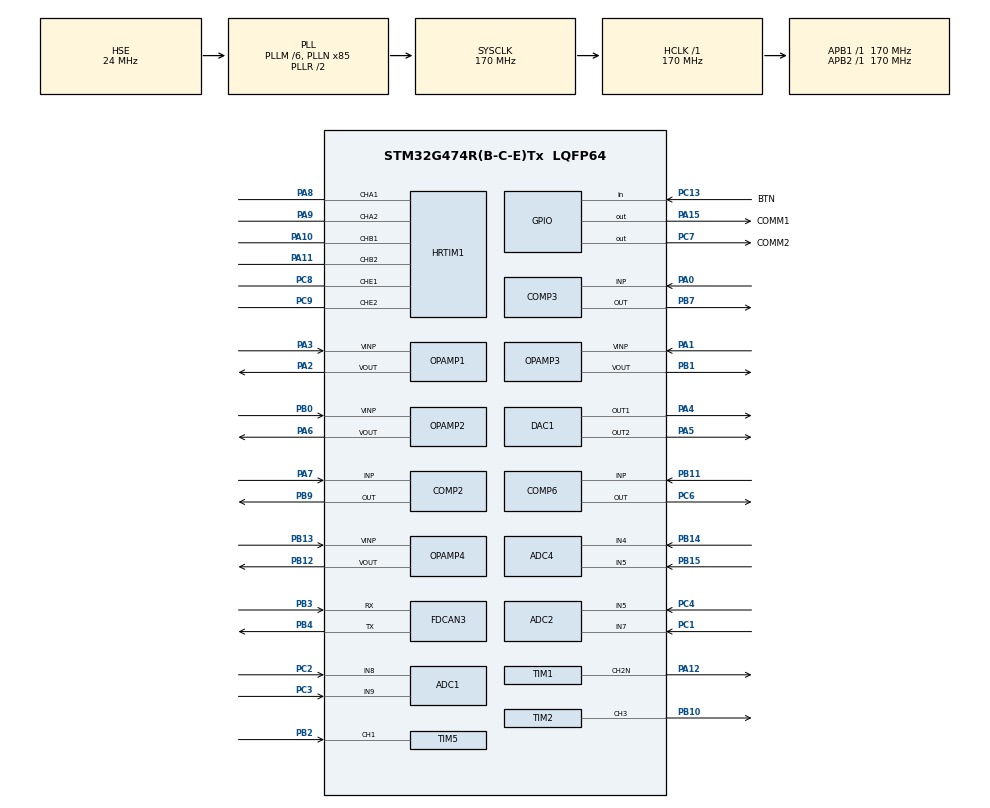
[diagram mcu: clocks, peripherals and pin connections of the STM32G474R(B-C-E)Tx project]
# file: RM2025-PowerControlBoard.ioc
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ADC1.AWD1HighThreshold=4095
ADC1.AWD2HighThreshold=4095
ADC1.AWD3HighThreshold=4095
ADC1.AWDChannel-8\#ChannelRegularConversion=ADC_CHANNEL_9
ADC1.AWDChannel-9\#ChannelRegularConversion=ADC_CHANNEL_8
ADC1.Channel-10\#ChannelRegularConversion=ADC_CHANNEL_12
ADC1.Channel-11\#ChannelRegularConversion=ADC_CHANNEL_3
ADC1.Channel-8\#ChannelRegularConversion=ADC_CHANNEL_9
ADC1.Channel-9\#ChannelRegularConversion=ADC_CHANNEL_8
ADC1.DMAAccessModeView=ENABLE
ADC1.DMAContinuousRequests=ENABLE
ADC1.EnableAnalogWatchDog1=true
ADC1.EnableAnalogWatchDog2=true
ADC1.EnableAnalogWatchDog3=true
ADC1.ExternalTrigConv=ADC_EXTERNALTRIG_HRTIM_TRG1
ADC1.Mode=ADC_DUALMODE_REGSIMULT
ADC1.MonitoredBy-10\#ChannelRegularConversion=__NULL
ADC1.MonitoredBy-11\#ChannelRegularConversion=__NULL
ADC1.MonitoredBy-8\#ChannelRegularConversion=ADC_ANALOGWATCHDOG_2
ADC1.MonitoredBy-9\#ChannelRegularConversion=ADC_ANALOGWATCHDOG_3
ADC1.NbrOfConversion=4
ADC1.NbrOfConversionFlag=1
ADC1.OffsetNumber-10\#ChannelRegularConversion=ADC_OFFSET_NONE
ADC1.OffsetNumber-11\#ChannelRegularConversion=ADC_OFFSET_NONE
ADC1.OffsetNumber-8\#ChannelRegularConversion=ADC_OFFSET_NONE
ADC1.OffsetNumber-9\#ChannelRegularConversion=ADC_OFFSET_NONE
ADC1.Overrun=ADC_OVR_DATA_OVERWRITTEN
ADC1.Rank-10\#ChannelRegularConversion=3
ADC1.Rank-11\#ChannelRegularConversion=4
ADC1.Rank-8\#ChannelRegularConversion=1
ADC1.Rank-9\#ChannelRegularConversion=2
ADC1.RegFilteringConfig-10\#ChannelRegularConversion=ADC_AWD_FILTERING_NONE
ADC1.RegFilteringConfig-8\#ChannelRegularConversion=ADC_AWD_FILTERING_NONE
ADC1.RegFilteringConfig-9\#ChannelRegularConversion=ADC_AWD_FILTERING_NONE
ADC1.SamplingTime-10\#ChannelRegularConversion=ADC_SAMPLETIME_12CYCLES_5
ADC1.SamplingTime-11\#ChannelRegularConversion=ADC_SAMPLETIME_12CYCLES_5
ADC1.SamplingTime-8\#ChannelRegularConversion=ADC_SAMPLETIME_12CYCLES_5
ADC1.SamplingTime-9\#ChannelRegularConversion=ADC_SAMPLETIME_12CYCLES_5
ADC1.WDG2ChannelR1=ADC_CHANNEL_9
ADC1.WDG3ChannelR2=ADC_CHANNEL_8
ADC1.WatchdogChannel=ADC_CHANNEL_12
ADC1.WatchdogMode2=ADC_ANALOGWATCHDOG_SINGLE_REGINJEC
ADC1.WatchdogMode3=ADC_ANALOGWATCHDOG_SINGLE_REGINJEC
ADC1.master=1
ADC2.AWD1HighThreshold=4095
ADC2.AWD2HighThreshold=4095
ADC2.AWD2ITMode=ENABLE
ADC2.AWDChannel-12\#ChannelRegularConversion=ADC_CHANNEL_5
ADC2.Channel-12\#ChannelRegularConversion=ADC_CHANNEL_5
ADC2.Channel-13\#ChannelRegularConversion=ADC_CHANNEL_3
ADC2.Channel-14\#ChannelRegularConversion=ADC_CHANNEL_3
ADC2.Channel-15\#ChannelRegularConversion=ADC_CHANNEL_7
ADC2.DMAAccessModeView=ENABLE
ADC2.DMAContinuousRequests=DISABLE
ADC2.EnableAnalogWatchDog1=true
ADC2.EnableAnalogWatchDog2=true
ADC2.EnableAnalogWatchDog3=false
ADC2.Mode=ADC_DUALMODE_REGSIMULT
ADC2.MonitoredBy-12\#ChannelRegularConversion=ADC_ANALOGWATCHDOG_2
ADC2.MonitoredBy-14\#ChannelRegularConversion=__NULL
ADC2.MonitoredBy-15\#ChannelRegularConversion=__NULL
ADC2.NbrOfConversion=4
ADC2.NbrOfConversionFlag=1
ADC2.OffsetNumber-12\#ChannelRegularConversion=ADC_OFFSET_NONE
ADC2.OffsetNumber-13\#ChannelRegularConversion=ADC_OFFSET_NONE
ADC2.OffsetNumber-14\#ChannelRegularConversion=ADC_OFFSET_NONE
ADC2.OffsetNumber-15\#ChannelRegularConversion=ADC_OFFSET_NONE
ADC2.Overrun=ADC_OVR_DATA_OVERWRITTEN
ADC2.Rank-12\#ChannelRegularConversion=1
ADC2.Rank-13\#ChannelRegularConversion=2
ADC2.Rank-14\#ChannelRegularConversion=3
ADC2.Rank-15\#ChannelRegularConversion=4
ADC2.RegFilteringConfig-12\#ChannelRegularConversion=ADC_AWD_FILTERING_NONE
ADC2.RegFilteringConfig-14\#ChannelRegularConversion=ADC_AWD_FILTERING_NONE
ADC2.SamplingTime-12\#ChannelRegularConversion=ADC_SAMPLETIME_12CYCLES_5
ADC2.SamplingTime-13\#ChannelRegularConversion=ADC_SAMPLETIME_12CYCLES_5
ADC2.SamplingTime-14\#ChannelRegularConversion=ADC_SAMPLETIME_12CYCLES_5
ADC2.SamplingTime-15\#ChannelRegularConversion=ADC_SAMPLETIME_12CYCLES_5
ADC2.WDG2ChannelR1=ADC_CHANNEL_5
ADC2.WatchdogChannel=ADC_CHANNEL_3
ADC2.WatchdogMode2=ADC_ANALOGWATCHDOG_SINGLE_REGINJEC
ADC4.Channel-3\#ChannelRegularConversion=ADC_CHANNEL_5
ADC4.Channel-4\#ChannelRegularConversion=ADC_CHANNEL_4
ADC4.DMAContinuousRequests=ENABLE
ADC4.ExternalTrigConv=ADC_SOFTWARE_START
ADC4.NbrOfConversion=2
ADC4.NbrOfConversionFlag=1
ADC4.OffsetNumber-3\#ChannelRegularConversion=ADC_OFFSET_NONE
ADC4.OffsetNumber-4\#ChannelRegularConversion=ADC_OFFSET_NONE
ADC4.Overrun=ADC_OVR_DATA_OVERWRITTEN
ADC4.Rank-3\#ChannelRegularConversion=1
ADC4.Rank-4\#ChannelRegularConversion=2
ADC4.SamplingTime-3\#ChannelRegularConversion=ADC_SAMPLETIME_247CYCLES_5
ADC4.SamplingTime-4\#ChannelRegularConversion=ADC_SAMPLETIME_92CYCLES_5
COMP2.Hysteresis=COMP_HYSTERESIS_NONE
COMP2.OutputPol=COMP_OUTPUTPOL_NONINVERTED
COMP2.TriggerMode=COMP_TRIGGERMODE_NONE
COMP3.TriggerMode=COMP_TRIGGERMODE_NONE
DAC1.DAC_Channel-DAC_OUT2_ExtAndInt=DAC_CHANNEL_2
DAC1.DAC_Channel-DAC_OUT2_Int=DAC_CHANNEL_2
DAC1.DAC_DMADoubleDataMode-DAC_OUT2_ExtAndInt=ENABLE
DAC1.DAC_HighFrequency_OUT1-DAC_OUT1_ExtAndInt=DAC_HIGH_FREQUENCY_INTERFACE_MODE_ABOVE_160MHZ
DAC1.DAC_HighFrequency_OUT2-DAC_OUT2_ExtAndInt=DAC_HIGH_FREQUENCY_INTERFACE_MODE_ABOVE_160MHZ
DAC1.DAC_HighFrequency_OUT2-DAC_OUT2_Int=DAC_HIGH_FREQUENCY_INTERFACE_MODE_ABOVE_160MHZ
DAC1.DAC_SampleAndHold-DAC_OUT1_ExtAndInt=DAC_SAMPLEANDHOLD_DISABLE
DAC1.DAC_SignedFormat-DAC_OUT2_ExtAndInt=ENABLE
DAC1.DAC_Trigger2_OUT1-DAC_OUT1_ExtAndInt=DAC_TRIGGER_HRTIM_STEP_TRG2
DAC1.DAC_Trigger2_OUT2-DAC_OUT2_ExtAndInt=DAC_TRIGGER_HRTIM_STEP_TRG1
DAC1.DAC_Trigger2_OUT2-DAC_OUT2_Int=DAC_TRIGGER_HRTIM_STEP_TRG1
DAC1.DAC_Trigger_OUT1-DAC_OUT1_ExtAndInt=DAC_TRIGGER_HRTIM_RST_TRG2
DAC1.DAC_Trigger_OUT2-DAC_OUT2_ExtAndInt=DAC_TRIGGER_HRTIM_RST_TRG1
DAC1.DAC_Trigger_OUT2-DAC_OUT2_Int=DAC_TRIGGER_HRTIM_RST_TRG1
DAC1.DAC_UserTrimming-DAC_OUT1_ExtAndInt=DAC_TRIMMING_FACTORY
DAC1.PolaritySawtooth2-DAC_OUT2_ExtAndInt=DAC_SAWTOOTH_POLARITY_INCREMENT
DAC1.ResetDataSawtooth-DAC_OUT1_ExtAndInt=2300
DAC1.ResetDataSawtooth2-DAC_OUT2_ExtAndInt=2300
DAC1.ResetDataSawtooth2-DAC_OUT2_Int=2300
DAC1.StepDataSawtooth-DAC_OUT1_ExtAndInt=500
DAC1.StepDataSawtooth2-DAC_OUT2_ExtAndInt=20
DAC1.StepDataSawtooth2-DAC_OUT2_Int=20
DAC1.WaveGeneration_OUT1-DAC_OUT1_ExtAndInt=SawtoothWaveGenerate
DAC1.WaveGeneration_OUT2-DAC_OUT2_ExtAndInt=SawtoothWaveGenerate
DAC1.WaveGeneration_OUT2-DAC_OUT2_Int=SawtoothWaveGenerate
Dma.ADC1.1.Direction=DMA_PERIPH_TO_MEMORY
Dma.ADC1.1.EventEnable=DISABLE
Dma.ADC1.1.Instance=DMA1_Channel1
Dma.ADC1.1.MemDataAlignment=DMA_MDATAALIGN_WORD
Dma.ADC1.1.MemInc=DMA_MINC_ENABLE
Dma.ADC1.1.Mode=DMA_CIRCULAR
Dma.ADC1.1.PeriphDataAlignment=DMA_PDATAALIGN_WORD
Dma.ADC1.1.PeriphInc=DMA_PINC_DISABLE
Dma.ADC1.1.Polarity=HAL_DMAMUX_REQ_GEN_RISING
Dma.ADC1.1.Priority=DMA_PRIORITY_VERY_HIGH
Dma.ADC1.1.RequestNumber=1
Dma.ADC1.1.SignalID=NONE
Dma.ADC1.1.SyncEnable=DISABLE
Dma.ADC1.1.SyncPolarity=HAL_DMAMUX_SYNC_NO_EVENT
Dma.ADC1.1.SyncRequestNumber=1
Dma.ADC1.1.SyncSignalID=NONE
Dma.ADC4.0.Direction=DMA_PERIPH_TO_MEMORY
Dma.ADC4.0.EventEnable=DISABLE
Dma.ADC4.0.Instance=DMA2_Channel2
Dma.ADC4.0.MemDataAlignment=DMA_MDATAALIGN_WORD
Dma.ADC4.0.MemInc=DMA_MINC_ENABLE
Dma.ADC4.0.Mode=DMA_CIRCULAR
Dma.ADC4.0.PeriphDataAlignment=DMA_PDATAALIGN_WORD
Dma.ADC4.0.PeriphInc=DMA_PINC_DISABLE
Dma.ADC4.0.Polarity=HAL_DMAMUX_REQ_GEN_RISING
Dma.ADC4.0.Priority=DMA_PRIORITY_HIGH
Dma.ADC4.0.RequestNumber=1
Dma.ADC4.0.SignalID=NONE
Dma.ADC4.0.SyncEnable=DISABLE
Dma.ADC4.0.SyncPolarity=HAL_DMAMUX_SYNC_NO_EVENT
Dma.ADC4.0.SyncRequestNumber=1
Dma.ADC4.0.SyncSignalID=NONE
Dma.HRTIM1_E.3.Direction=DMA_MEMORY_TO_PERIPH
Dma.HRTIM1_E.3.EventEnable=DISABLE
Dma.HRTIM1_E.3.Instance=DMA1_Channel2
Dma.HRTIM1_E.3.MemDataAlignment=DMA_MDATAALIGN_WORD
Dma.HRTIM1_E.3.MemInc=DMA_MINC_ENABLE
Dma.HRTIM1_E.3.Mode=DMA_CIRCULAR
Dma.HRTIM1_E.3.PeriphDataAlignment=DMA_PDATAALIGN_WORD
Dma.HRTIM1_E.3.PeriphInc=DMA_PINC_DISABLE
Dma.HRTIM1_E.3.Polarity=HAL_DMAMUX_REQ_GEN_RISING
Dma.HRTIM1_E.3.Priority=DMA_PRIORITY_HIGH
Dma.HRTIM1_E.3.RequestNumber=1
Dma.HRTIM1_E.3.SignalID=NONE
Dma.HRTIM1_E.3.SyncEnable=DISABLE
Dma.HRTIM1_E.3.SyncPolarity=HAL_DMAMUX_SYNC_NO_EVENT
Dma.HRTIM1_E.3.SyncRequestNumber=1
Dma.HRTIM1_E.3.SyncSignalID=NONE
Dma.Request0=ADC4
Dma.Request1=ADC1
Dma.Request2=TIM2_CH3
Dma.Request3=HRTIM1_E
Dma.TIM2_CH3.2.Direction=DMA_MEMORY_TO_PERIPH
Dma.TIM2_CH3.2.EventEnable=DISABLE
Dma.TIM2_CH3.2.Instance=DMA2_Channel1
Dma.TIM2_CH3.2.MemDataAlignment=DMA_MDATAALIGN_WORD
Dma.TIM2_CH3.2.MemInc=DMA_MINC_ENABLE
Dma.TIM2_CH3.2.Mode=DMA_NORMAL
Dma.TIM2_CH3.2.PeriphDataAlignment=DMA_PDATAALIGN_WORD
Dma.TIM2_CH3.2.PeriphInc=DMA_PINC_DISABLE
Dma.TIM2_CH3.2.Polarity=HAL_DMAMUX_REQ_GEN_RISING
Dma.TIM2_CH3.2.Priority=DMA_PRIORITY_MEDIUM
Dma.TIM2_CH3.2.RequestNumber=1
Dma.TIM2_CH3.2.SignalID=NONE
Dma.TIM2_CH3.2.SyncEnable=DISABLE
Dma.TIM2_CH3.2.SyncPolarity=HAL_DMAMUX_SYNC_NO_EVENT
Dma.TIM2_CH3.2.SyncRequestNumber=1
Dma.TIM2_CH3.2.SyncSignalID=NONE
FDCAN3.CalculateBaudRateNominal=1000000
FDCAN3.CalculateTimeBitNominal=1000
FDCAN3.CalculateTimeQuantumNominal=100.0
FDCAN3.DataPrescaler=1
FDCAN3.DataTimeSeg1=1
FDCAN3.DataTimeSeg2=1
FDCAN3.NominalPrescaler=17
FDCAN3.NominalTimeSeg1=7
FDCAN3.NominalTimeSeg2=2
FDCAN3.StdFiltersNbr=1
HRTIM1.ADCTrigger1_Source1=HRTIM_ADCTRIGGEREVENT13_MASTER_CMP1
HRTIM1.ADCTrigger2_Source1=HRTIM_ADCTRIGGEREVENT24_MASTER_CMP3
HRTIM1.ADCTrigger_Id1=HRTIM_ADCTRIGGER_1
HRTIM1.ADCTrigger_Id2=HRTIM_ADCTRIGGER_2
HRTIM1.CaptureUnit1-Output_TA1TA2=__NULL
HRTIM1.CaptureUnit1-Output_TB1TB2=__NULL
HRTIM1.CaptureUnit2-Output_TA1TA2=__NULL
HRTIM1.CaptureUnit2-Output_TB1TB2=__NULL
HRTIM1.CompareUnit1-MasterTimer=HRTIM_COMPAREUNIT_1
HRTIM1.CompareUnit1-Output_TA1TA2=HRTIM_COMPAREUNIT_1
HRTIM1.CompareUnit1-Output_TB1TB2=HRTIM_COMPAREUNIT_1
HRTIM1.CompareUnit1-Output_TE1TE2=HRTIM_COMPAREUNIT_1
HRTIM1.CompareUnit2-MasterTimer=HRTIM_COMPAREUNIT_2
HRTIM1.CompareUnit2-Output_TA1TA2=HRTIM_COMPAREUNIT_2
HRTIM1.CompareUnit2-Output_TB1TB2=HRTIM_COMPAREUNIT_2
HRTIM1.CompareUnit2-Output_TE1TE2=__NULL
HRTIM1.CompareUnit3-MasterTimer=HRTIM_COMPAREUNIT_3
HRTIM1.CompareUnit3-Output_TA1TA2=HRTIM_COMPAREUNIT_3
HRTIM1.CompareUnit3-Output_TB1TB2=HRTIM_COMPAREUNIT_3
HRTIM1.CompareUnit3-Output_TE1TE2=HRTIM_COMPAREUNIT_3
HRTIM1.CompareUnit4-Output_TA1TA2=HRTIM_COMPAREUNIT_4
HRTIM1.CompareUnit4-Output_TB1TB2=HRTIM_COMPAREUNIT_4
HRTIM1.CompareUnit4-Output_TE1TE2=__NULL
HRTIM1.CompareValue1-MasterTimer=5000-416
HRTIM1.CompareValue1-Output_TA1TA2=0
HRTIM1.CompareValue1-Output_TB1TB2=0
HRTIM1.CompareValue1-Output_TE1TE2=0
HRTIM1.CompareValue2-MasterTimer=10880
HRTIM1.CompareValue2-Output_TA1TA2=1088
HRTIM1.CompareValue2-Output_TB1TB2=1088
HRTIM1.CompareValue3-MasterTimer=15000-2848
HRTIM1.CompareValue3-Output_TA1TA2=19000
HRTIM1.CompareValue3-Output_TB1TB2=8000
HRTIM1.CompareValue3-Output_TE1TE2=0
HRTIM1.CompareValue4-Output_TA1TA2=2176
HRTIM1.CompareValue4-Output_TB1TB2=2176
HRTIM1.CounterFaultLine5=0
HRTIM1.DACSynchro-Output_TA1TA2=HRTIM_DACSYNC_NONE
HRTIM1.DMADstAddress-Output_TE1TE2=(uint32_t)&(hhrtim1.Instance->sTimerxRegs[HRTIM_TIMERINDEX_TIMER_E].CMP1xR)
HRTIM1.DMARequests1-Output_TE1TE2=HRTIM_TIM_DMA_RST
HRTIM1.DMASize-Output_TE1TE2=4
HRTIM1.DMASrcAddress-Output_TE1TE2=(uint32_t)&timerE_Duty_DMA_Buffer[0]
HRTIM1.DeadTimeInsertion-Output_TA1TA2=HRTIM_TIMDEADTIMEINSERTION_ENABLED
HRTIM1.DeadTimeInsertion-Output_TB1TB2=HRTIM_TIMDEADTIMEINSERTION_ENABLED
HRTIM1.DeadTimeInsertion-Output_TE1TE2=HRTIM_TIMDEADTIMEINSERTION_ENABLED
HRTIM1.Deadtimeconfig-Output_TE1TE2=HRTIM_TIMERINDEX_TIMER_E
HRTIM1.DualChannelDacEnableFake_TA-Output_TA1TA2=HRTIM_TIMER_DCDE_ENABLED_FAKE1
HRTIM1.DualChannelDacEnableFake_TB-Output_TB1TB2=HRTIM_TIMER_DCDE_ENABLED_FAKE1
HRTIM1.Event1-Output_TA1TA2=__NULL
HRTIM1.Event1-Output_TE1TE2=__NULL
HRTIM1.Event2-Output_TA1TA2=__NULL
HRTIM1.Event5-Output_TB1TB2=__NULL
HRTIM1.Event6-Output_TA1TA2=HRTIM_EVENT_6
HRTIM1.Event6-Output_TB1TB2=__NULL
HRTIM1.Event8-Output_TA1TA2=__NULL
HRTIM1.Event8-Output_TB1TB2=HRTIM_EVENT_8
HRTIM1.Event_EEV1=HRTIM_EVENT_1
HRTIM1.Event_EEV2=HRTIM_EVENT_2
HRTIM1.Event_EEV3=HRTIM_EVENT_3
HRTIM1.Event_EEV4=HRTIM_EVENT_4
HRTIM1.Event_EEV5=HRTIM_EVENT_5
HRTIM1.Event_EEV6=HRTIM_EVENT_6
HRTIM1.Event_EEV7=__NULL
HRTIM1.Event_EEV8=HRTIM_EVENT_8
HRTIM1.Event_EEV9=__NULL
HRTIM1.FallingSign-Output_TA1TA2=HRTIM_TIMDEADTIME_FALLINGSIGN_POSITIVE
HRTIM1.FallingValue-Output_TA1TA2=40
HRTIM1.FallingValue-Output_TB1TB2=40
HRTIM1.FallingValue-Output_TE1TE2=40
HRTIM1.FaultEnable_Source1-Output_TA1TA2=HRTIM_TIMFAULTENABLE_FAULT1
HRTIM1.FaultEnable_Source1-Output_TB1TB2=HRTIM_TIMFAULTENABLE_FAULT1
HRTIM1.FaultEnable_Source2-Output_TA1TA2=HRTIM_TIMFAULTENABLE_FAULT2
HRTIM1.FaultEnable_Source2-Output_TB1TB2=HRTIM_TIMFAULTENABLE_FAULT2
HRTIM1.FaultEnable_Source3-Output_TA1TA2=HRTIM_TIMFAULTENABLE_FAULT3
HRTIM1.FaultEnable_Source3-Output_TB1TB2=HRTIM_TIMFAULTENABLE_FAULT3
HRTIM1.FaultEnable_Source4-Output_TA1TA2=HRTIM_TIMFAULTENABLE_FAULT4
HRTIM1.FaultEnable_Source4-Output_TB1TB2=HRTIM_TIMFAULTENABLE_FAULT4
HRTIM1.FaultEnable_Source5-Output_TA1TA2=HRTIM_TIMFAULTENABLE_FAULT5
HRTIM1.FaultEnable_Source5-Output_TB1TB2=HRTIM_TIMFAULTENABLE_FAULT5
HRTIM1.FaultLevel1-Output_TA1TA2=HRTIM_OUTPUTFAULTLEVEL_INACTIVE
HRTIM1.FaultLevel1-Output_TB1TB2=HRTIM_OUTPUTFAULTLEVEL_INACTIVE
HRTIM1.FaultLevel2-Output_TA1TA2=HRTIM_OUTPUTFAULTLEVEL_INACTIVE
HRTIM1.FaultLevel2-Output_TB1TB2=HRTIM_OUTPUTFAULTLEVEL_INACTIVE
HRTIM1.FaultLock-Output_TB1TB2=HRTIM_TIMFAULTLOCK_READWRITE
HRTIM1.Fault_Line1=HRTIM_FAULT_1
HRTIM1.Fault_Line2=HRTIM_FAULT_2
HRTIM1.Fault_Line3=HRTIM_FAULT_3
HRTIM1.Fault_Line4=HRTIM_FAULT_4
HRTIM1.Fault_Line5=HRTIM_FAULT_5
HRTIM1.Filter6-Output_TA1TA2=HRTIM_TIMEEVFLT_BLANKINGCMP4
HRTIM1.Filter8-Output_TB1TB2=HRTIM_TIMEEVFLT_BLANKINGCMP4
HRTIM1.Filter_FaultLine1=HRTIM_FAULTFILTER_3
HRTIM1.Filter_FaultLine2=HRTIM_FAULTFILTER_3
HRTIM1.Filter_FaultLine3=HRTIM_FAULTFILTER_6
HRTIM1.Filter_FaultLine4=HRTIM_FAULTFILTER_3
HRTIM1.Filter_FaultLine5=HRTIM_FAULTFILTER_9
HRTIM1.GreaterCMP1_TA=HRTIM_TIMERGTCMP1_EQUAL
HRTIM1.GreaterCMP3_TA=HRTIM_TIMERGTCMP3_EQUAL
HRTIM1.HRTIMInterruptResquests1=HRTIM_IT_NONE
HRTIM1.IdleLevel1-Output_TA1TA2=HRTIM_OUTPUTIDLELEVEL_INACTIVE
HRTIM1.IdleLevel2-Output_TA1TA2=HRTIM_OUTPUTIDLELEVEL_INACTIVE
HRTIM1.InterruptRequests1_Master=HRTIM_MASTER_IT_MUPD
HRTIM1.NumberADCTriggerSource1=1
HRTIM1.NumberADCTriggerSource2=1
HRTIM1.NumberDMARequests_TB=0
HRTIM1.NumberDMARequests_TE=1
HRTIM1.NumberFaultEnable-Output_TA1TA2=5
HRTIM1.NumberFaultEnable-Output_TB1TB2=5
HRTIM1.NumberInterruptRequests-Output_TA1TA2=0
HRTIM1.NumberInterruptRequests_Master-MasterTimer=1
HRTIM1.NumberResetSource1-Output_TA1TA2=1
HRTIM1.NumberResetSource1-Output_TB1TB2=1
HRTIM1.NumberResetSource1-Output_TE1TE2=1
HRTIM1.NumberResetTrigger-Output_TA1TA2=1
HRTIM1.NumberResetTrigger-Output_TB1TB2=1
HRTIM1.NumberResetTrigger-Output_TE1TE2=1
HRTIM1.NumberSetSource1-Output_TA1TA2=2
HRTIM1.NumberSetSource1-Output_TB1TB2=2
HRTIM1.NumberSetSource1-Output_TE1TE2=1
HRTIM1.NumberUpdateTrigger-Output_TA1TA2=1
HRTIM1.NumberUpdateTrigger-Output_TB1TB2=1
HRTIM1.NumberUpdateTrigger-Output_TE1TE2=1
HRTIM1.Periode_MASTER=21760
HRTIM1.Periode_TA=21760
HRTIM1.Periode_TB=21760
HRTIM1.Periode_TE=21760
HRTIM1.Polarity1-Output_TA1TA2=HRTIM_OUTPUTPOLARITY_HIGH
HRTIM1.Polarity2-Output_TA1TA2=HRTIM_OUTPUTPOLARITY_HIGH
HRTIM1.Polarity_EEV6=HRTIM_EVENTPOLARITY_LOW
HRTIM1.Polarity_EEV8=HRTIM_EVENTPOLARITY_LOW
HRTIM1.PreloadEnable-Output_TA1TA2=HRTIM_PRELOAD_ENABLED
HRTIM1.PreloadEnable-Output_TE1TE2=HRTIM_PRELOAD_ENABLED
HRTIM1.RepetitionCounter-MasterTimer=4-1
HRTIM1.RepetitionUpdate-Output_TA1TA2=HRTIM_UPDATEONREPETITION_ENABLED
HRTIM1.RepetitionUpdate-Output_TB1TB2=HRTIM_UPDATEONREPETITION_ENABLED
HRTIM1.RepetitionUpdate-Output_TE1TE2=HRTIM_UPDATEONREPETITION_ENABLED
HRTIM1.ResetModeFaultLine5=HRTIM_FAULTCOUNTERRST_UNCONDITIONAL
HRTIM1.ResetOutput1_Source1-Output_TA1TA2=HRTIM_OUTPUTRESET_TIMCMP1
HRTIM1.ResetOutput1_Source1-Output_TB1TB2=HRTIM_OUTPUTRESET_TIMCMP1
HRTIM1.ResetOutput1_Source1-Output_TE1TE2=HRTIM_OUTPUTRESET_TIMCMP1
HRTIM1.ResetTrigger1-Output_TA1TA2=HRTIM_TIMRESETTRIGGER_MASTER_PER
HRTIM1.ResetTrigger1-Output_TB1TB2=HRTIM_TIMRESETTRIGGER_MASTER_CMP2
HRTIM1.ResetTrigger1-Output_TE1TE2=HRTIM_TIMRESETTRIGGER_MASTER_PER
HRTIM1.RisingSign-Output_TA1TA2=HRTIM_TIMDEADTIME_RISINGSIGN_POSITIVE
HRTIM1.RisingValue-Output_TA1TA2=40
HRTIM1.RisingValue-Output_TB1TB2=40
HRTIM1.RisingValue-Output_TE1TE2=40
HRTIM1.SetOutput1_Source1-Output_TA1TA2=HRTIM_OUTPUTSET_TIMCMP3
HRTIM1.SetOutput1_Source1-Output_TB1TB2=HRTIM_OUTPUTSET_TIMCMP3
HRTIM1.SetOutput1_Source1-Output_TE1TE2=HRTIM_OUTPUTSET_TIMCMP3
HRTIM1.SetOutput1_Source2-Output_TA1TA2=HRTIM_OUTPUTSET_EEV_6
HRTIM1.SetOutput1_Source2-Output_TB1TB2=HRTIM_OUTPUTSET_EEV_8
HRTIM1.Source_EEV1=HRTIM_EEV1SRC_ADC1_AWD1
HRTIM1.Source_EEV2=HRTIM_EEV2SRC_ADC1_AWD2
HRTIM1.Source_EEV3=HRTIM_EEV3SRC_ADC1_AWD3
HRTIM1.Source_EEV4=HRTIM_EEV4SRC_ADC2_AWD1
HRTIM1.Source_EEV5=HRTIM_EEV5SRC_ADC2_AWD2
HRTIM1.Source_EEV8=HRTIM_EEV8SRC_COMP3_OUT
HRTIM1.Source_FaultLine1=HRTIM_FAULTSOURCE_EEVINPUT
HRTIM1.Source_FaultLine2=HRTIM_FAULTSOURCE_EEVINPUT
HRTIM1.Source_FaultLine3=HRTIM_FAULTSOURCE_EEVINPUT
HRTIM1.Source_FaultLine4=HRTIM_FAULTSOURCE_EEVINPUT
HRTIM1.Source_FaultLine5=HRTIM_FAULTSOURCE_EEVINPUT
HRTIM1.SwapA=__NULL
HRTIM1.UpdateTrigger1-Output_TA1TA2=HRTIM_TIMUPDATETRIGGER_MASTER
HRTIM1.UpdateTrigger1-Output_TB1TB2=HRTIM_TIMUPDATETRIGGER_MASTER
HRTIM1.UpdateTrigger1-Output_TE1TE2=HRTIM_TIMUPDATETRIGGER_MASTER
Mcu.Family=STM32G4
Mcu.Name=STM32G474R(B-C-E)Tx
Mcu.Package=LQFP64
Mcu.UserConstants=DEAD_TIME,60
NVIC.FDCAN3_IT0_IRQn=true\:1\:0\:true\:false\:false\:true\:true\:true
NVIC.HRTIM1_FLT_IRQn=true\:0\:0\:false\:false\:false\:true\:true\:true
NVIC.HRTIM1_Master_IRQn=true\:0\:0\:false\:false\:false\:true\:true\:true
NVIC.PriorityGroup=NVIC_PRIORITYGROUP_4
NVIC.TIM20_TRG_COM_IRQn=true\:2\:0\:true\:false\:true\:true\:true\:true
NVIC.TIM20_UP_IRQn=true\:2\:0\:true\:false\:true\:true\:true\:true
NVIC.TIM6_DAC_IRQn=true\:2\:0\:true\:false\:true\:true\:true\:true
OPAMP2.PowerMode=OPAMP_POWERMODE_HIGHSPEED
OPAMP3.PowerMode=OPAMP_POWERMODE_HIGHSPEED
PA0.Mode=INP
PA0.Signal=COMP3_INP
PA1.Mode=Follower
PA1.Signal=OPAMP3_VINP
PA10.Mode=Output_TB1TB2
PA10.Signal=HRTIM1_CHB1
PA11.Mode=Output_TB1TB2
PA11.Signal=HRTIM1_CHB2
PA12.Mode=PWM Generation2 CH2N
PA12.Signal=TIM1_CH2N
PA13.Mode=Serial_Wire
PA13.Signal=SYS_JTMS-SWDIO
PA14.Mode=Serial_Wire
PA14.Signal=SYS_JTCK-SWCLK
PA15.GPIO_Label=COMM1
PA15.GPIO_Speed=GPIO_SPEED_FREQ_VERY_HIGH
PA15.Signal=GPIO_Output
PA2.Signal=SharedAnalog_PA2
PA3.Mode=Follower
PA3.Signal=OPAMP1_VINP
PA4.Signal=COMP_DAC11_group
PA5.Signal=COMP_DAC12_group
PA6.Signal=SharedAnalog_PA6
PA7.Mode=INP
PA7.Signal=COMP2_INP
PA8.Mode=Output_TA1TA2
PA8.Signal=HRTIM1_CHA1
PA9.Mode=Output_TA1TA2
PA9.Signal=HRTIM1_CHA2
PB0.Mode=Follower
PB0.Signal=OPAMP2_VINP
PB1.Signal=SharedAnalog_PB1
PB10.Signal=S_TIM2_CH3
PB11.Mode=INP
PB11.Signal=COMP6_INP
PB12.Mode=Follower
PB12.Signal=OPAMP4_VOUT
PB13.Mode=Follower
PB13.Signal=OPAMP4_VINP
PB14.Mode=IN4-Single-Ended
PB14.Signal=ADC4_IN4
PB15.Mode=IN5-Single-Ended
PB15.Signal=ADC4_IN5
PB2.Signal=S_TIM5_CH1
PB3.GPIO_Speed=GPIO_SPEED_FREQ_LOW
PB3.Mode=FDCAN_Activate
PB3.Signal=FDCAN3_RX
PB4.Mode=FDCAN_Activate
PB4.Signal=FDCAN3_TX
PB7.Mode=ExternalOutput
PB7.Signal=COMP3_OUT
PB9.GPIO_FM9=__NULL
PB9.GPIO_Speed=GPIO_SPEED_FREQ_LOW
PB9.Mode=ExternalOutput
PB9.Signal=COMP2_OUT
PC1.Mode=IN7-Single-Ended
PC1.Signal=ADC2_IN7
PC13.GPIO_Label=BTN
PC13.GPIO_PuPd=GPIO_PULLUP
PC13.Signal=GPIO_Input
PC2.Mode=IN8-Single-Ended
PC2.Signal=ADC1_IN8
PC3.Mode=IN9-Single-Ended
PC3.Signal=ADC1_IN9
PC4.Mode=IN5-Single-Ended
PC4.Signal=ADC2_IN5
PC6.Mode=ExternalOutput
PC6.Signal=COMP6_OUT
PC7.GPIO_Label=COMM2
PC7.Signal=GPIO_Output
PC8.Mode=Output_TE1TE2
PC8.Signal=HRTIM1_CHE1
PC9.Mode=Output_TE1TE2
PC9.Signal=HRTIM1_CHE2
PF0-OSC_IN.Mode=HSE-External-Oscillator
PF0-OSC_IN.Signal=RCC_OSC_IN
PF1-OSC_OUT.Mode=HSE-External-Oscillator
PF1-OSC_OUT.Signal=RCC_OSC_OUT
ProjectManager.HeapSize=0x200
ProjectManager.StackSize=0x400
ProjectManager.TargetToolchain=Makefile
RCC.ADC12Freq_Value=170000000
RCC.ADC345Freq_Value=170000000
RCC.AHBFreq_Value=170000000
RCC.APB1Freq_Value=170000000
RCC.APB1TimFreq_Value=170000000
RCC.APB2Freq_Value=170000000
RCC.APB2TimFreq_Value=170000000
RCC.CortexFreq_Value=170000000
RCC.EXTERNAL_CLOCK_VALUE=12288000
RCC.HCLKFreq_Value=170000000
RCC.HSE_VALUE=24000000
RCC.HSI48_VALUE=48000000
RCC.HSI_VALUE=16000000
RCC.LSE_VALUE=32768
RCC.PLLM=RCC_PLLM_DIV6
RCC.PLLN=85
RCC.PLLSourceVirtual=RCC_PLLSOURCE_HSE
RCC.RCC_MCO1Source=RCC_MCO1SOURCE_HSE
RCC.SYSCLKFreq_VALUE=170000000
RCC.SYSCLKSource=RCC_SYSCLKSOURCE_PLLCLK
RCC.USBFreq_Value=170000000
RCC.VCOOutputFreq_Value=340000000
SH.COMP_DAC11_group.0=DAC1_OUT1,DAC_OUT1_ExtAndInt
SH.COMP_DAC12_group.0=DAC1_OUT2,DAC_OUT2_ExtAndInt
SH.S_TIM2_CH3.0=TIM2_CH3,PWM Generation3 CH3
SH.S_TIM5_CH1.0=TIM5_CH1,Input_Capture1_from_TI1
SH.SharedAnalog_PA2.0=OPAMP1_VOUT,Follower
SH.SharedAnalog_PA2.1=ADC1_IN3,IN3-Single-Ended
SH.SharedAnalog_PA6.0=OPAMP2_VOUT,Follower
SH.SharedAnalog_PA6.1=ADC2_IN3,IN3-Single-Ended
SH.SharedAnalog_PB1.0=OPAMP3_VOUT,Follower
SH.SharedAnalog_PB1.1=ADC1_IN12,IN12-Single-Ended
SYS.TrimmingMode=__NULL
SYS.VoltageScaling=SYSCFG_VREFBUF_VOLTAGE_SCALE2
TIM1.AutoReloadPreload=TIM_AUTORELOAD_PRELOAD_ENABLE
TIM1.Channel-PWM\ Generation2\ CH2N=TIM_CHANNEL_2
TIM1.OCFastMode_PWM-PWM\ Generation2\ CH2N=TIM_OCFAST_DISABLE
TIM1.OCNIdleState_2=TIM_OCNIDLESTATE_SET
TIM1.OCNPolarity_2=TIM_OCNPOLARITY_HIGH
TIM1.PeriodNoDither=2500-1
TIM1.Prescaler=17-1
TIM1.PulseNoDither_2=0
TIM1.RepetitionCounter=0
TIM2.Channel-PWM\ Generation3\ CH3=TIM_CHANNEL_3
TIM2.PeriodNoDither=213-1
TIM20.PeriodNoDither=213-1
TIM3.PeriodNoDither=213-1
TIM3.Prescaler=0
TIM5.AutoReloadPreload=TIM_AUTORELOAD_PRELOAD_ENABLE
TIM5.Channel-Input_Capture1_from_TI1=TIM_CHANNEL_1
TIM6.PeriodNoDither=250-1
TIM6.Prescaler=170-1
TIM6.TIM_MasterOutputTrigger=TIM_TRGO_RESET
VP_COMP2_VS_DAC1OUT2.Mode=INM_DAC1OUT2
VP_COMP3_VS_DAC1OUT1.Mode=INM_DAC1OUT1
VP_COMP6_VS_VREFINT14.Mode=VREFINT_14
VP_HRTIM1_VS_hrtimMasterTimerNoOutput.Mode=MasterTimer
VP_SYS_VS_DBSignals.Mode=DisableDeadBatterySignals
VP_TIM16_VS_ClockSourceINT.Mode=Enable_Timer
VP_TIM1_VS_ClockSourceINT.Mode=Internal
VP_TIM20_VS_ClockSourceINT.Mode=Internal
VP_TIM2_VS_ClockSourceINT.Mode=Internal
VP_TIM3_VS_ClockSourceINT.Mode=Internal
VP_TIM5_VS_ClockSourceINT.Mode=Internal
VP_TIM6_VS_ClockSourceINT.Mode=Enable_Timer
VREF+.Mode=InternalMode
VREF+.Signal=VREFBUF_OUT
board=custom

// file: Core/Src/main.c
/* USER CODE BEGIN Header */
/**
  ******************************************************************************
  * @file           : main.c
  * @brief          : Main program body
  ******************************************************************************
  * @attention
  *
  * Copyright (c) 2025 STMicroelectronics.
  * All rights reserved.
  *
  * This software is licensed under terms that can be found in the LICENSE file
  * in the root directory of this software component.
  * If no LICENSE file comes with this software, it is provided AS-IS.
  *
  ******************************************************************************
  */
/* USER CODE END Header */
#include "main.h"
#include "adc.h"
#include "comp.h"
#include "dac.h"
#include "dma.h"
#include "fdcan.h"
#include "hrtim.h"
#include "opamp.h"
#include "tim.h"
#include "gpio.h"

void SystemClock_Config(void);

int main(void)
{

  /* MCU Configuration--------------------------------------------------------*/

  /* Reset of all peripherals, Initializes the Flash interface and the Systick. */
  HAL_Init();

  /* Configure the system clock */
  SystemClock_Config();

  /* Initialize all configured peripherals */
  MX_GPIO_Init();
  MX_DMA_Init();
  MX_HRTIM1_Init();
  MX_ADC1_Init();
  MX_ADC2_Init();
  MX_FDCAN3_Init();
  MX_TIM1_Init();
  MX_TIM3_Init();
  MX_TIM6_Init();
  MX_TIM5_Init();
  MX_ADC4_Init();
  MX_TIM20_Init();
  MX_TIM16_Init();
  MX_COMP3_Init();
  MX_DAC1_Init();
  MX_OPAMP2_Init();
  MX_COMP2_Init();
  MX_COMP6_Init();
  MX_OPAMP3_Init();
  MX_OPAMP4_Init();
  MX_TIM2_Init();
  MX_OPAMP1_Init();
  /* USER CODE BEGIN 2 */
  extern void systemStart(void);
  systemStart();
  /* USER CODE END 2 */

  /* Infinite loop */
  while (1)
  {

  }
}

void SystemClock_Config(void)
{
  RCC_OscInitTypeDef RCC_OscInitStruct = {0};
  RCC_ClkInitTypeDef RCC_ClkInitStruct = {0};

  /** Configure the main internal regulator output voltage
  */
  HAL_PWREx_ControlVoltageScaling(PWR_REGULATOR_VOLTAGE_SCALE1_BOOST);

  /** Initializes the RCC Oscillators according to the specified parameters
  * in the RCC_OscInitTypeDef structure.
  */
  RCC_OscInitStruct.OscillatorType = RCC_OSCILLATORTYPE_HSE;
  RCC_OscInitStruct.HSEState = RCC_HSE_ON;
  RCC_OscInitStruct.PLL.PLLState = RCC_PLL_ON;
  RCC_OscInitStruct.PLL.PLLSource = RCC_PLLSOURCE_HSE;
  RCC_OscInitStruct.PLL.PLLM = RCC_PLLM_DIV6;
  RCC_OscInitStruct.PLL.PLLN = 85;
  RCC_OscInitStruct.PLL.PLLP = RCC_PLLP_DIV2;
  RCC_OscInitStruct.PLL.PLLQ = RCC_PLLQ_DIV2;
  RCC_OscInitStruct.PLL.PLLR = RCC_PLLR_DIV2;
  if (HAL_RCC_OscConfig(&RCC_OscInitStruct) != HAL_OK)
  {
    Error_Handler();
  }

  /** Initializes the CPU, AHB and APB buses clocks
  */
  RCC_ClkInitStruct.ClockType = RCC_CLOCKTYPE_HCLK|RCC_CLOCKTYPE_SYSCLK
                              |RCC_CLOCKTYPE_PCLK1|RCC_CLOCKTYPE_PCLK2;
  RCC_ClkInitStruct.SYSCLKSource = RCC_SYSCLKSOURCE_PLLCLK;
  RCC_ClkInitStruct.AHBCLKDivider = RCC_SYSCLK_DIV1;
  RCC_ClkInitStruct.APB1CLKDivider = RCC_HCLK_DIV1;
  RCC_ClkInitStruct.APB2CLKDivider = RCC_HCLK_DIV1;

  if (HAL_RCC_ClockConfig(&RCC_ClkInitStruct, FLASH_LATENCY_4) != HAL_OK)
  {
    Error_Handler();
  }
}

void Error_Handler(void)
{
  __disable_irq();
  while (1)
  {
  }
}
